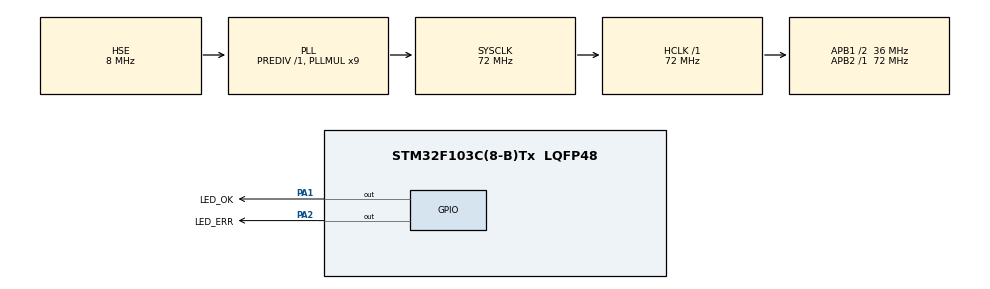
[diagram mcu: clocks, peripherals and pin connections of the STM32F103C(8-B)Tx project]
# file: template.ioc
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FREERTOS.Tasks01=defaultTask,24,128,StartDefaultTask,As weak,NULL,Dynamic,NULL,NULL;testTask,24,128,StartTestTask,As external,NULL,Dynamic,NULL,NULL
Mcu.Family=STM32F1
Mcu.Name=STM32F103C(8-B)Tx
Mcu.Package=LQFP48
NVIC.PriorityGroup=NVIC_PRIORITYGROUP_4
NVIC.TIM1_UP_IRQn=true\:0\:0\:false\:false\:true\:false\:false\:true
NVIC.TimeBase=TIM1_UP_IRQn
NVIC.TimeBaseIP=TIM1
PA1.GPIO_Label=LED_OK
PA1.GPIO_Speed=GPIO_SPEED_FREQ_HIGH
PA1.PinState=GPIO_PIN_SET
PA1.Signal=GPIO_Output
PA13.Mode=Serial_Wire
PA13.Signal=SYS_JTMS-SWDIO
PA14.Mode=Serial_Wire
PA14.Signal=SYS_JTCK-SWCLK
PA2.GPIO_Label=LED_ERR
PA2.GPIO_ModeDefaultOutputPP=GPIO_MODE_OUTPUT_PP
PA2.GPIO_PuPd=GPIO_NOPULL
PA2.GPIO_Speed=GPIO_SPEED_FREQ_HIGH
PA2.PinState=GPIO_PIN_SET
PA2.Signal=GPIO_Output
PD0-OSC_IN.Mode=HSE-External-Oscillator
PD0-OSC_IN.Signal=RCC_OSC_IN
PD1-OSC_OUT.Mode=HSE-External-Oscillator
PD1-OSC_OUT.Signal=RCC_OSC_OUT
ProjectManager.HeapSize=0x200
ProjectManager.StackSize=0x400
ProjectManager.TargetToolchain=Other Toolchains (GPDSC)
RCC.AHBFreq_Value=72000000
RCC.APB1CLKDivider=RCC_HCLK_DIV2
RCC.APB1Freq_Value=36000000
RCC.APB1TimFreq_Value=72000000
RCC.APB2Freq_Value=72000000
RCC.APB2TimFreq_Value=72000000
RCC.HCLKFreq_Value=72000000
RCC.PLLMUL=RCC_PLL_MUL9
RCC.PLLSourceVirtual=RCC_PLLSOURCE_HSE
RCC.SYSCLKFreq_VALUE=72000000
RCC.SYSCLKSource=RCC_SYSCLKSOURCE_PLLCLK
RCC.USBFreq_Value=72000000
VP_FREERTOS_VS_CMSIS_V2.Mode=CMSIS_V2
VP_SYS_VS_tim1.Mode=TIM1
board=custom

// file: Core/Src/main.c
/* USER CODE BEGIN Header */
/**
  ******************************************************************************
  * @file           : main.c
  * @brief          : Main program body
  ******************************************************************************
  * @attention
  *
  * <h2><center>&copy; Copyright (c) 2020 STMicroelectronics.
  * All rights reserved.</center></h2>
  *
  * This software component is licensed by ST under Ultimate Liberty license
  * SLA0044, the "License"; You may not use this file except in compliance with
  * the License. You may obtain a copy of the License at:
  *                             www.st.com/SLA0044
  *
  ******************************************************************************
  */
/* USER CODE END Header */

#include "main.h"
#include "cmsis_os.h"

/* USER CODE BEGIN Includes */
#include "task_default.hpp"
#include "task_test.hpp"
/* USER CODE END Includes */

/* Definitions for defaultTask */
osThreadId_t defaultTaskHandle;
const osThreadAttr_t defaultTask_attributes = {
  .name = "defaultTask",
  .priority = (osPriority_t) osPriorityNormal,
  .stack_size = 128
};
/* Definitions for testTask */
osThreadId_t testTaskHandle;
const osThreadAttr_t testTask_attributes = {
  .name = "testTask",
  .priority = (osPriority_t) osPriorityNormal,
  .stack_size = 128
};

void SystemClock_Config(void);
static void MX_GPIO_Init(void);
void StartDefaultTask(void *argument);
extern void StartTestTask(void *argument);

int main(void)
{

  /* MCU Configuration--------------------------------------------------------*/

  /* Reset of all peripherals, Initializes the Flash interface and the Systick. */
  HAL_Init();

  /* Configure the system clock */
  SystemClock_Config();

  /* Initialize all configured peripherals */
  MX_GPIO_Init();
  /* Init scheduler */
  osKernelInitialize();

  /* Create the thread(s) */
  /* creation of defaultTask */
  defaultTaskHandle = osThreadNew(StartDefaultTask, NULL, &defaultTask_attributes);

  /* creation of testTask */
  testTaskHandle = osThreadNew(StartTestTask, NULL, &testTask_attributes);

  /* Start scheduler */
  osKernelStart();

  /* We should never get here as control is now taken by the scheduler */

  /* Infinite loop */
  while (1)
  {

  }
}

void SystemClock_Config(void)
{
  RCC_OscInitTypeDef RCC_OscInitStruct = {0};
  RCC_ClkInitTypeDef RCC_ClkInitStruct = {0};

  /** Initializes the CPU, AHB and APB busses clocks
  */
  RCC_OscInitStruct.OscillatorType = RCC_OSCILLATORTYPE_HSE;
  RCC_OscInitStruct.HSEState = RCC_HSE_ON;
  RCC_OscInitStruct.HSEPredivValue = RCC_HSE_PREDIV_DIV1;
  RCC_OscInitStruct.HSIState = RCC_HSI_ON;
  RCC_OscInitStruct.PLL.PLLState = RCC_PLL_ON;
  RCC_OscInitStruct.PLL.PLLSource = RCC_PLLSOURCE_HSE;
  RCC_OscInitStruct.PLL.PLLMUL = RCC_PLL_MUL9;
  if (HAL_RCC_OscConfig(&RCC_OscInitStruct) != HAL_OK)
  {
    Error_Handler();
  }
  /** Initializes the CPU, AHB and APB busses clocks
  */
  RCC_ClkInitStruct.ClockType = RCC_CLOCKTYPE_HCLK|RCC_CLOCKTYPE_SYSCLK
                              |RCC_CLOCKTYPE_PCLK1|RCC_CLOCKTYPE_PCLK2;
  RCC_ClkInitStruct.SYSCLKSource = RCC_SYSCLKSOURCE_PLLCLK;
  RCC_ClkInitStruct.AHBCLKDivider = RCC_SYSCLK_DIV1;
  RCC_ClkInitStruct.APB1CLKDivider = RCC_HCLK_DIV2;
  RCC_ClkInitStruct.APB2CLKDivider = RCC_HCLK_DIV1;

  if (HAL_RCC_ClockConfig(&RCC_ClkInitStruct, FLASH_LATENCY_2) != HAL_OK)
  {
    Error_Handler();
  }
}

static void MX_GPIO_Init(void)
{
  GPIO_InitTypeDef GPIO_InitStruct = {0};

  /* GPIO Ports Clock Enable */
  __HAL_RCC_GPIOD_CLK_ENABLE();
  __HAL_RCC_GPIOA_CLK_ENABLE();

  /*Configure GPIO pin Output Level */
  HAL_GPIO_WritePin(GPIOA, LED_OK_Pin|LED_ERR_Pin, GPIO_PIN_SET);

  /*Configure GPIO pins : LED_OK_Pin LED_ERR_Pin */
  GPIO_InitStruct.Pin = LED_OK_Pin|LED_ERR_Pin;
  GPIO_InitStruct.Mode = GPIO_MODE_OUTPUT_PP;
  GPIO_InitStruct.Pull = GPIO_NOPULL;
  GPIO_InitStruct.Speed = GPIO_SPEED_FREQ_HIGH;
  HAL_GPIO_Init(GPIOA, &GPIO_InitStruct);

}

__weak void StartDefaultTask(void *argument)
{
  for(;;)
  {
    osDelay(1);
  }
}

void HAL_TIM_PeriodElapsedCallback(TIM_HandleTypeDef *htim)
{
  if (htim->Instance == TIM1) {
    HAL_IncTick();
  }
}

void Error_Handler(void)
{
}

/************************ (C) COPYRIGHT STMicroelectronics *****END OF FILE****/
